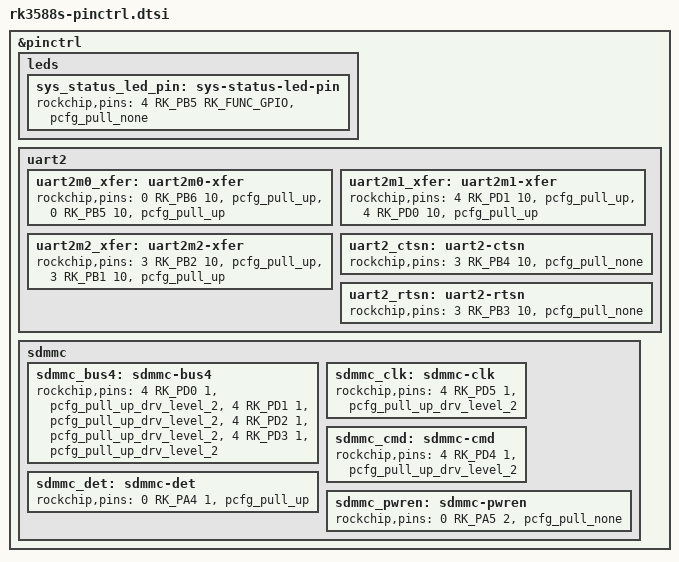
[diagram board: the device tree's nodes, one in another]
// SPDX-License-Identifier: (GPL-2.0+ OR MIT)
/*
 * Copyright (c) 2021 Rockchip Electronics Co., Ltd.
 */

#include <dt-bindings/pinctrl/rockchip.h>
#include <dt-bindings/gpio/gpio.h>
#include "rk3588s_pinconf.dtsi"

/*
 * This file is auto generated by pin2dts tool, please keep these code
 * by adding changes at end of this file.
 */
&pinctrl {

	leds {
		sys_status_led_pin: sys-status-led-pin {
			rockchip,pins = <4 RK_PB5 RK_FUNC_GPIO &pcfg_pull_none>;
		};
	};

	uart2 {
		/omit-if-no-ref/
		uart2m0_xfer: uart2m0-xfer {
			rockchip,pins =
				/* uart2_rx_m0 */
				<0 RK_PB6 10 &pcfg_pull_up>,
				/* uart2_tx_m0 */
				<0 RK_PB5 10 &pcfg_pull_up>;
		};

		/omit-if-no-ref/
		uart2m1_xfer: uart2m1-xfer {
			rockchip,pins =
				/* uart2_rx_m1 */
				<4 RK_PD1 10 &pcfg_pull_up>,
				/* uart2_tx_m1 */
				<4 RK_PD0 10 &pcfg_pull_up>;
		};

		/omit-if-no-ref/
		uart2m2_xfer: uart2m2-xfer {
			rockchip,pins =
				/* uart2_rx_m2 */
				<3 RK_PB2 10 &pcfg_pull_up>,
				/* uart2_tx_m2 */
				<3 RK_PB1 10 &pcfg_pull_up>;
		};

		/omit-if-no-ref/
		uart2_ctsn: uart2-ctsn {
			rockchip,pins =
				/* uart2_ctsn */
				<3 RK_PB4 10 &pcfg_pull_none>;
		};

		/omit-if-no-ref/
		uart2_rtsn: uart2-rtsn {
			rockchip,pins =
				/* uart2_rtsn */
				<3 RK_PB3 10 &pcfg_pull_none>;
		};
	};

	sdmmc {
		/omit-if-no-ref/
		sdmmc_bus4: sdmmc-bus4 {
			rockchip,pins =
				/* sdmmc_d0 */
				<4 RK_PD0 1 &pcfg_pull_up_drv_level_2>,
				/* sdmmc_d1 */
				<4 RK_PD1 1 &pcfg_pull_up_drv_level_2>,
				/* sdmmc_d2 */
				<4 RK_PD2 1 &pcfg_pull_up_drv_level_2>,
				/* sdmmc_d3 */
				<4 RK_PD3 1 &pcfg_pull_up_drv_level_2>;
		};

		/omit-if-no-ref/
		sdmmc_clk: sdmmc-clk {
			rockchip,pins =
				/* sdmmc_clk */
				<4 RK_PD5 1 &pcfg_pull_up_drv_level_2>;
		};

		/omit-if-no-ref/
		sdmmc_cmd: sdmmc-cmd {
			rockchip,pins =
				/* sdmmc_cmd */
				<4 RK_PD4 1 &pcfg_pull_up_drv_level_2>;
		};

		/omit-if-no-ref/
		sdmmc_det: sdmmc-det {
			rockchip,pins =
				/* sdmmc_det */
				<0 RK_PA4 1 &pcfg_pull_up>;
		};

		/omit-if-no-ref/
		sdmmc_pwren: sdmmc-pwren {
			rockchip,pins =
				/* sdmmc_pwren */
				<0 RK_PA5 2 &pcfg_pull_none>;
		};
	};

};

